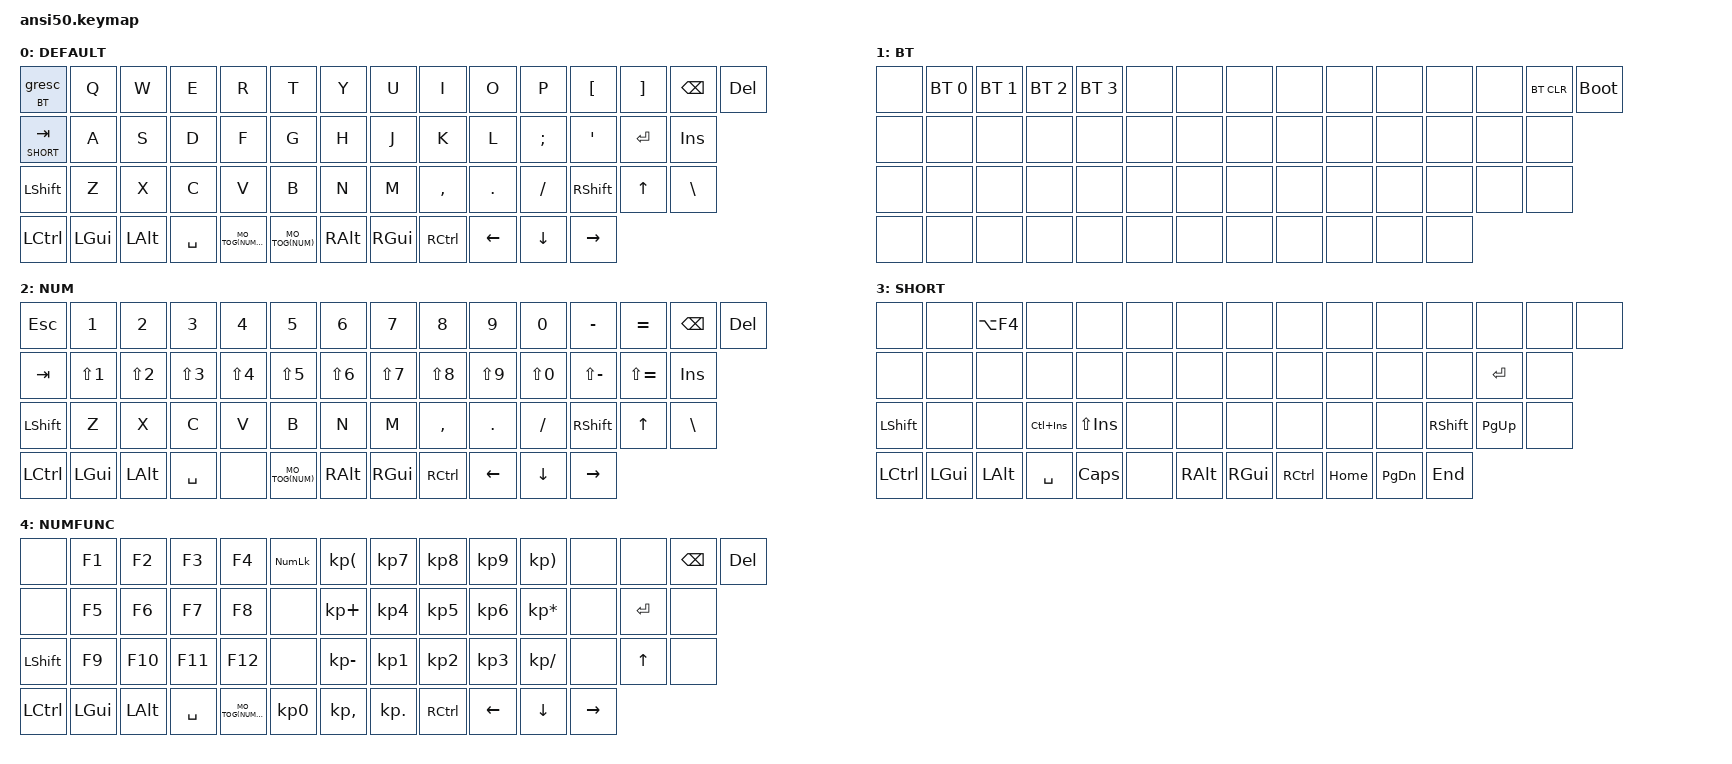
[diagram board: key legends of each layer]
#include <behaviors.dtsi>
#include <dt-bindings/zmk/keys.h>
#include <dt-bindings/zmk/bt.h>

#define DEFAULT 0
#define BT 1
#define NUM 2
#define SHORT 3
#define NUMFUNC 4

#define MO_TOG(layer) &mo_tog layer layer   // Macro to apply momentary-layer-on-hold/toggle-layer-on-tap to a specific layer

/ {
    combos {
        compatible = "zmk,combos";

        combo_bracket_round_l {
          timeout-ms = <50>;
          global-quick-tap-ms = <300>;

          key-positions = <22 23>;
          bindings = <&kp LPAR>;
        };
        combo_bracket_round_r {
          timeout-ms = <50>;
          global-quick-tap-ms = <300>;

          key-positions = <23 24>;
          bindings = <&kp RPAR>;
        };
        combo_parentheses_chevrons {
          timeout-ms = <50>;
          global-quick-tap-ms = <300>;

          key-positions = <22 23 24>;
          bindings = <&parentheses_chevrons>;
        };

        combo_bracket_square_l {
          timeout-ms = <50>;
          global-quick-tap-ms = <300>;

          key-positions = <36 37>;
          bindings = <&kp LBKT>;
        };
        combo_bracket_square_r {
          timeout-ms = <50>;
          global-quick-tap-ms = <300>;

          key-positions = <37 38>;
          bindings = <&kp RBKT>;
        };
    };
};


/ {
    behaviors {
        mo_tog: behavior_mo_tog {
            compatible = "zmk,behavior-hold-tap";
            label = "mo_tog";
            #binding-cells = <2>;
            flavor = "hold-preferred";
            tapping-term-ms = <200>;
            bindings = <&mo>, <&tog>;
        };
        gresc: grave_escape {
            compatible = "zmk,behavior-mod-morph";
            label = "GRAVE_ESCAPE";
            #binding-cells = <0>;
            bindings = <&kp ESC>, <&kp GRAVE>;
            mods = <(MOD_LGUI|MOD_LSFT|MOD_RGUI|MOD_RSFT)>;
            keep-mods = <(MOD_LSFT)>;
        };
        grvescbt: behavior_layer_esc_grv {
            compatible = "zmk,behavior-hold-tap";
            label = "grvescbt";
            #binding-cells = <2>;
            flavor = "hold-preferred";
            tapping-term-ms = <200>;
            bindings = <&mo>, <&gresc>;
        };
        parentheses_chevrons: parentheses_chevrons {
            compatible = "zmk,behavior-mod-morph";
            label = "parentheses_chevrons";
            #binding-cells = <0>;
            bindings = <&parentheses>, <&chevrons>;
            mods = <(MOD_LSFT)>;
        };
    };

    macros {
        parentheses: parentheses {
            label = "parentheses";
            compatible = "zmk,behavior-macro";
            #binding-cells = <0>;
            bindings
                = <&macro_tap &kp LPAR &kp RPAR &kp LEFT>
                ;
        };
        chevrons: chevrons {
            label = "chevrons";
            compatible = "zmk,behavior-macro";
            #binding-cells = <0>;
            wait-ms = <10>;
            tap-ms = <10>;
            bindings
                = <&macro_tap &kp LT &kp GT &kp LEFT>
                ;
        };
    };
    
    keymap {
        compatible = "zmk,keymap";

        DEFAULT {
            bindings = <
    &grvescbt BT 0     &kp Q     &kp W     &kp E      &kp R            &kp T        &kp Y     &kp U     &kp I      &kp O     &kp P      &kp LBKT   &kp RBKT   &kp BSPC  &kp DEL
    &lt SHORT TAB      &kp A     &kp S     &kp D      &kp F            &kp G        &kp H     &kp J     &kp K      &kp L     &kp SEMI   &kp APOS   &kp ENTER  &kp INS
    &kp LSHFT          &kp Z     &kp X     &kp C      &kp V            &kp B        &kp N     &kp M     &kp COMMA  &kp DOT   &kp SLASH  &kp RSHFT  &kp UP     &kp BSLH
    &kp LCTRL          &kp LGUI  &kp LALT  &kp SPACE  MO_TOG(NUMFUNC)  MO_TOG(NUM)  &kp RALT  &kp RGUI  &kp RCTRL  &kp LEFT  &kp DOWN   &kp RIGHT
            >;
        };
        BT {
            bindings = <
    &none     &bt BT_SEL 0 &bt BT_SEL 1 &bt BT_SEL 2 &bt BT_SEL 3 &none     &none     &none    &none     &none     &none     &none   &none    &bt BT_CLR &bootloader
    &none     &none        &none        &none        &none        &none     &none     &none    &none     &none     &none     &none   &none    &none
    &none     &none        &none        &none        &none        &none     &none     &none    &none     &none     &none     &none   &none    &none
    &none     &none        &none        &none        &none        &none     &none     &none    &none     &none     &none     &none
            >;
        };
        NUM {
            bindings = <
    &kp ESC   &kp N1     &kp N2     &kp N3      &kp N4      &kp N5      &kp N6      &kp N7     &kp N8      &kp N9      &kp N0      &kp MINUS     &kp EQUAL     &kp BSPC  &kp DEL
    &kp TAB   &kp LS(N1) &kp LS(N2) &kp LS(N3)  &kp LS(N4)  &kp LS(N5)  &kp LS(N6)  &kp LS(N7) &kp LS(N8)  &kp LS(N9)  &kp LS(N0)  &kp LS(MINUS) &kp LS(EQUAL) &kp INS
    &kp LSHFT &kp Z      &kp X      &kp C       &kp V       &kp B       &kp N       &kp M      &kp COMMA   &kp DOT     &kp SLASH   &kp RSHFT     &kp UP        &kp BSLH
    &kp LCTRL &kp LGUI   &kp LALT   &kp SPACE   &none       MO_TOG(NUM) &kp RALT    &kp RGUI   &kp RCTRL   &kp LEFT    &kp DOWN    &kp RIGHT
            >;
        };
        SHORT {
            bindings = <
    &none        &none      &kp LA(F4) &none        &none        &none       &none       &none      &none       &none       &none       &none         &none       &none  &none
    &none        &none      &none      &none        &none        &none       &none       &none      &none       &none       &none       &none         &kp ENTER   &none
    &kp LSHFT    &none      &none      &kp LC(INS)  &kp LS(INS)  &none       &none       &none      &none       &none       &none       &kp RSHFT     &kp PG_UP   &none
    &kp LCTRL    &kp LGUI   &kp LALT   &kp SPACE    &kp CAPS     &none       &kp RALT    &kp RGUI   &kp RCTRL   &kp HOME    &kp PG_DN   &kp END
            >;
        };
        NUMFUNC {
            bindings = <
    &none        &kp F1     &kp F2     &kp F3      &kp F4           &kp KP_NLCK &kp KP_LPAR   &kp KP_N7  &kp KP_N8   &kp KP_N9   &kp KP_RPAR      &none      &none         &kp BSPC  &kp DEL
    &none        &kp F5     &kp F6     &kp F7      &kp F8           &none       &kp KP_PLUS   &kp KP_N4  &kp KP_N5   &kp KP_N6   &kp KP_MULTIPLY  &none      &kp ENTER     &none
    &kp LSHFT    &kp F9     &kp F10    &kp F11     &kp F12          &none       &kp KP_MINUS  &kp KP_N1  &kp KP_N2   &kp KP_N3   &kp KP_SLASH     &none      &kp UP     &none
    &kp LCTRL    &kp LGUI   &kp LALT   &kp SPACE   MO_TOG(NUMFUNC)  &kp KP_N0   &kp KP_COMMA  &kp KP_DOT &kp RCTRL   &kp LEFT    &kp DOWN         &kp RIGHT
            >;
        };
    };
};
